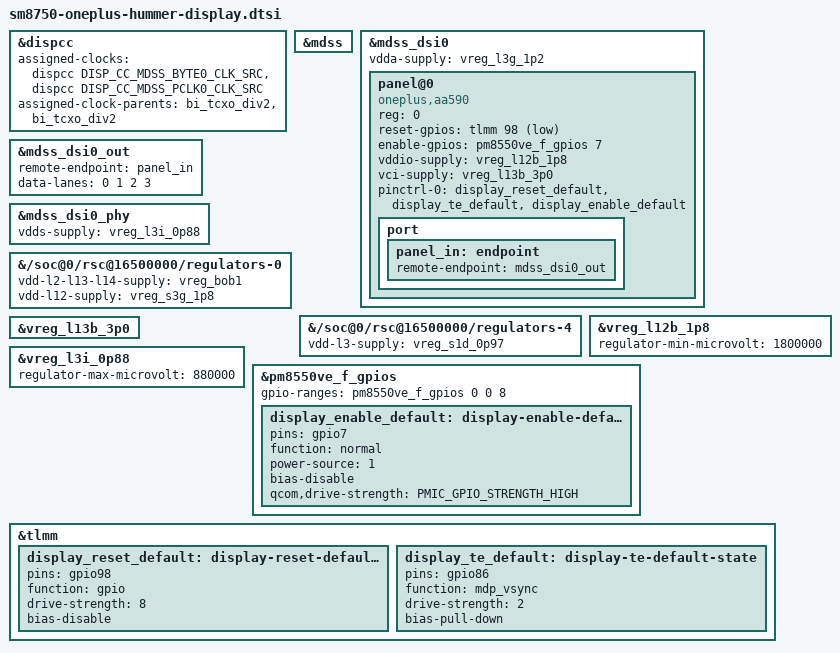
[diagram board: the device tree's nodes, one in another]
#include <dt-bindings/pinctrl/qcom,pmic-gpio.h>

&dispcc {
	assigned-clocks = <&dispcc DISP_CC_MDSS_BYTE0_CLK_SRC>,
			  <&dispcc DISP_CC_MDSS_PCLK0_CLK_SRC>;
	assigned-clock-parents = <&bi_tcxo_div2>, <&bi_tcxo_div2>;
};

&mdss {
	status = "okay";
};

&mdss_dsi0 {
	vdda-supply = <&vreg_l3g_1p2>;
	status = "okay";

	panel@0 {
		compatible = "oneplus,aa590";
		reg = <0>;
		reset-gpios = <&tlmm 98 GPIO_ACTIVE_LOW>;
		enable-gpios = <&pm8550ve_f_gpios 7 GPIO_ACTIVE_HIGH>;
		vddio-supply = <&vreg_l12b_1p8>;
		vci-supply = <&vreg_l13b_3p0>;
		pinctrl-0 = <&display_reset_default>, <&display_te_default>,
			    <&display_enable_default>;
		pinctrl-names = "default";

		port {
			panel_in: endpoint {
				remote-endpoint = <&mdss_dsi0_out>;
			};
		};
	};
};

&mdss_dsi0_out {
	remote-endpoint = <&panel_in>;
	data-lanes = <0 1 2 3>;
};

&mdss_dsi0_phy {
	vdds-supply = <&vreg_l3i_0p88>;
	status = "okay";
};

&{/soc@0/rsc@16500000/regulators-0} {
	vdd-l2-l13-l14-supply = <&vreg_bob1>;
	vdd-l12-supply = <&vreg_s3g_1p8>;
};

&{/soc@0/rsc@16500000/regulators-4} {
	vdd-l3-supply = <&vreg_s1d_0p97>;
};

&vreg_l12b_1p8 {
	regulator-min-microvolt = <1800000>;
	status = "okay";
};

&vreg_l13b_3p0 {
	status = "okay";
};

&vreg_l3i_0p88 {
	regulator-max-microvolt = <880000>;
	status = "okay";
};

&pm8550ve_f_gpios {
	gpio-ranges = <&pm8550ve_f_gpios 0 0 8>;

	display_enable_default: display-enable-default-state {
		pins = "gpio7";
		function = "normal";
		power-source = <1>;
		bias-disable;
		qcom,drive-strength = <PMIC_GPIO_STRENGTH_HIGH>;
	};
};

&tlmm {
	display_reset_default: display-reset-default-state {
		pins = "gpio98";
		function = "gpio";
		drive-strength = <8>;
		bias-disable;
	};

	display_te_default: display-te-default-state {
		pins = "gpio86";
		function = "mdp_vsync";
		drive-strength = <2>;
		bias-pull-down;
	};
};
